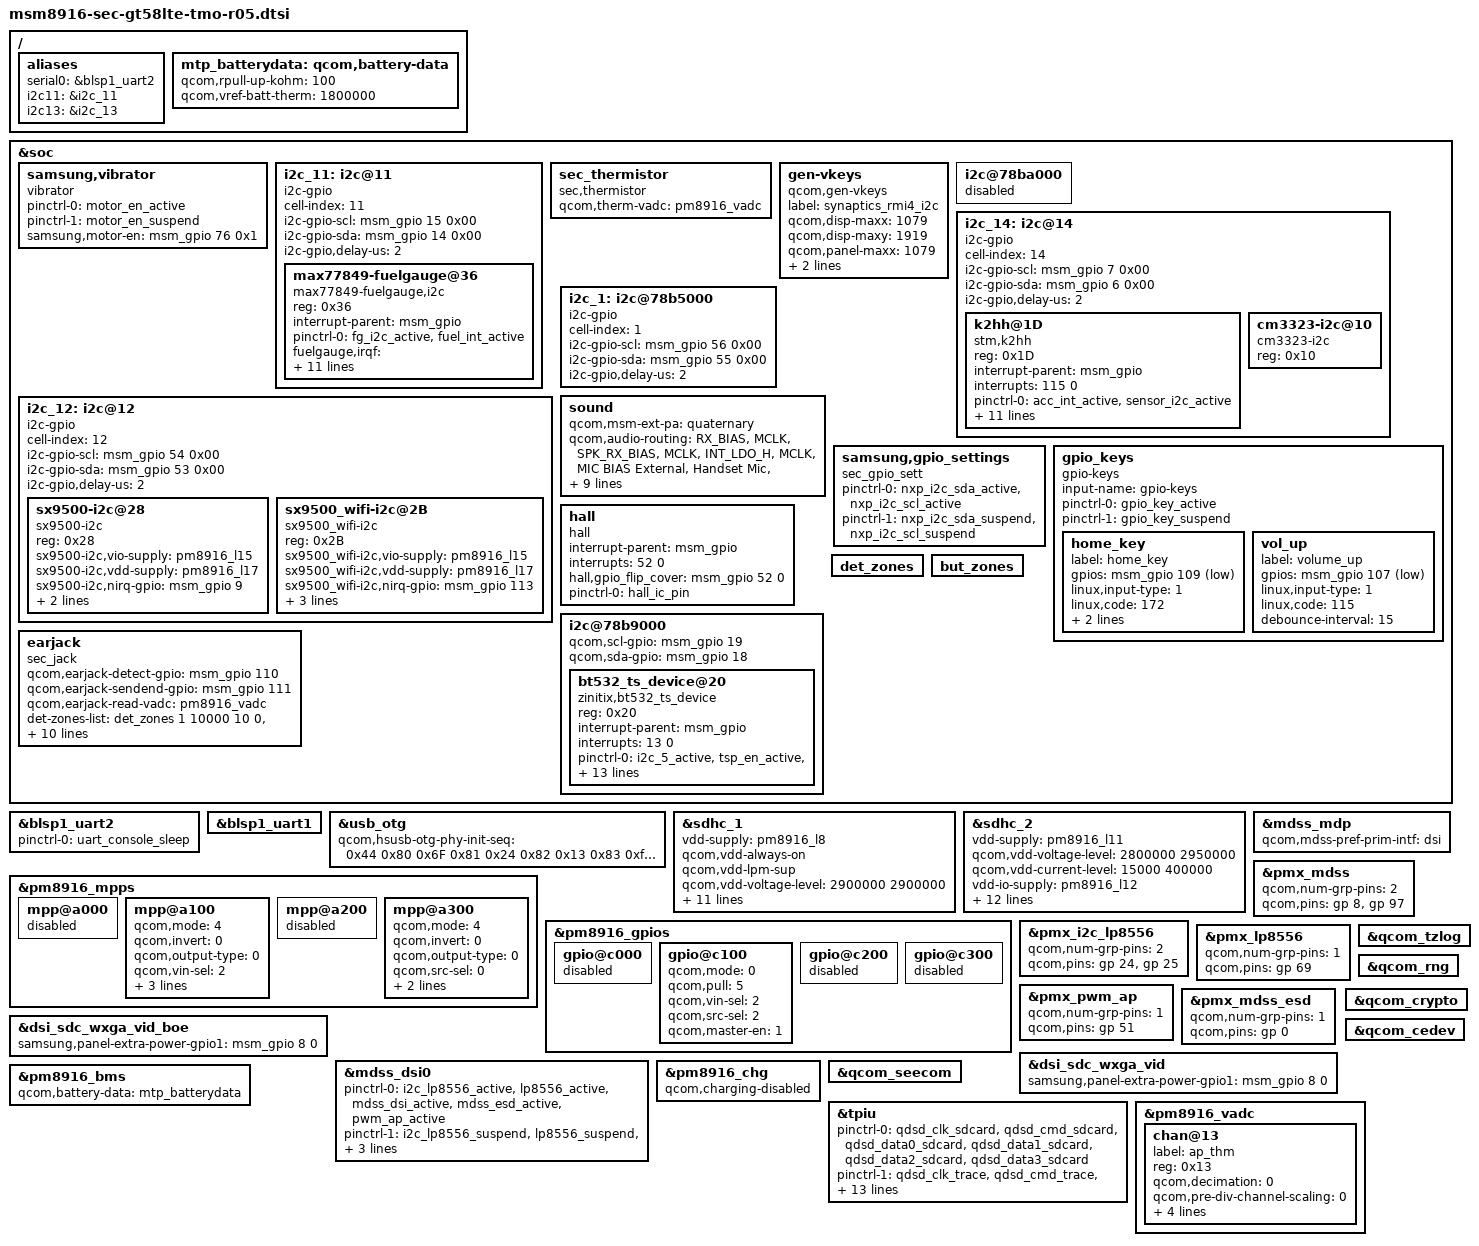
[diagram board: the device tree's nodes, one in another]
/* Copyright (c) 2014, The Linux Foundation. All rights reserved.
 *
 * This program is free software; you can redistribute it and/or modify
 * it under the terms of the GNU General Public License version 2 and
 * only version 2 as published by the Free Software Foundation.
 *
 * This program is distributed in the hope that it will be useful,
 * but WITHOUT ANY WARRANTY; without even the implied warranty of
 * MERCHANTABILITY or FITNESS FOR A PARTICULAR PURPOSE.  See the
 * GNU General Public License for more details.
 */

#include "msm8916.dtsi"
#include "msm8916-pinctrl-sec-gt58lte-tmo-r05.dtsi"
#include "msm8916-camera-sensor-gt58.dtsi"
#include "msm8916-sec-gt5note8lte-tmo-battery-r00.dtsi"
#include "msm8916-max77849-gt5note8-r01.dtsi"
#include "../../../../../../drivers/video/msm/mdss/samsung/S6D7AA0_LSL080AL03/dsi_panel_S6D7AA0_LSL080AL03_xga_video.dtsi"
#include "../../../../../../drivers/video/msm/mdss/samsung/S6D7AA0_LSL080AL03_BOE/dsi_panel_S6D7AA0_LSL080AL03_BOE_xga_video.dtsi"
/ {
	aliases {
		serial0 = &blsp1_uart2;
		i2c11 = &i2c_11;
		i2c13 = &i2c_13;
	};
};

&soc {
	samsung,vibrator {
	        pinctrl-names = "tlmm_motor_en_active","tlmm_motor_en_suspend";
	        pinctrl-0 = <&motor_en_active>;
	        pinctrl-1 = <&motor_en_suspend>;
	        compatible = "vibrator";
	        samsung,motor-en = <&msm_gpio 76 0x1>;
	        status = "ok";
	};

       i2c_11:i2c@11 {
		cell-index = <11>;
		compatible = "i2c-gpio";
		i2c-gpio-scl = <&msm_gpio 15 0x00>;
		i2c-gpio-sda = <&msm_gpio 14 0x00>;
		i2c-gpio,delay-us = <2>;
		#address-cells = <1>;
		#size-cells = <0>;

		max77849-fuelgauge@36{
			compatible = "max77849-fuelgauge,i2c";
			reg = <0x36>;
			interrupt-parent = <&msm_gpio>;
			pinctrl-names = "default";
			pinctrl-0 = <&fg_i2c_active &fuel_int_active>;
			fuelgauge,irqf = "IRQF_TRIGGER_FALLING + IRQF_ONESHOT + IRQF_NO_SUSPEND";
			fuelgauge,fuel_int = <&msm_gpio 121 0x1>;
			fuelgauge,capacity_max = <1000>;
			fuelgauge,capacity_max_margin = <50>;
			fuelgauge,capacity_min = <0>;
			fuelgauge,capacity_calculation_type = <0x1F>;
			fuelgauge,fuel_alert_soc = <1>;
			fuelgauge,using_temp_compensation;
			fuelgauge,low_temp_limit = <(-100)>;
			fuelgauge,low_temp_recovery = <(-80)>;
			fuelgauge,low_temp_valrt = <0xAA>;		/* VALRT is 3400V */
		};
	};

	sec_thermistor {
		compatible = "sec,thermistor";
		qcom,therm-vadc = <&pm8916_vadc>;
	};

	gen-vkeys {
		compatible = "qcom,gen-vkeys";
		label = "synaptics_rmi4_i2c";
		qcom,disp-maxx = <1079>;
		qcom,disp-maxy = <1919>;
		qcom,panel-maxx = <1079>;
		qcom,panel-maxy = <2084>;
		qcom,key-codes = <158 139 172 217>;
	};

	i2c@78ba000 { /* BLSP1 QUP6 */
		status = "disabled";
	};

       i2c_14:i2c@14 {
		cell-index = <14>;
		compatible = "i2c-gpio";
		i2c-gpio-scl = <&msm_gpio 7 0x00>;
		i2c-gpio-sda = <&msm_gpio 6 0x00>;
		i2c-gpio,delay-us = <2>;
		#address-cells = <1>;
		#size-cells = <0>;
		k2hh@1D {
			compatible = "stm,k2hh";
			reg = <0x1D>;
			interrupt-parent = <&msm_gpio>;
			interrupts = <115 0>;
			pinctrl-names = "default";
			pinctrl-0 = <&acc_int_active &sensor_i2c_active>;
			stm,irq_gpio = <&msm_gpio 115 0x00>;
			stm,vio-supply = <&pm8916_l5>;
			stm,vdd-supply = <&pm8916_l17>;
			stm,axis_map_x = <1>;
			stm,axis_map_y = <0>;
			stm,axis_map_z = <2>;
			stm,negate_x = <1>;
			stm,negate_y = <0>;
			stm,negate_z = <1>;
			stm,poll_interval = <100>;
			stm,min_interval = <2>;
		};
		cm3323-i2c@10 {
			compatible = "cm3323-i2c";
			reg = <0x10>;
		};
	};

	i2c_12:i2c@12 {
		cell-index = <12>;
		compatible = "i2c-gpio";
		i2c-gpio-scl = <&msm_gpio 54 0x00>;
		i2c-gpio-sda = <&msm_gpio 53 0x00>;
		i2c-gpio,delay-us = <2>;
		#address-cells = <1>;
		#size-cells = <0>;
		sx9500-i2c@28 {
			compatible = "sx9500-i2c";
			reg = <0x28>;
			sx9500-i2c,vio-supply = <&pm8916_l15>;
			sx9500-i2c,vdd-supply = <&pm8916_l17>;
			sx9500-i2c,nirq-gpio = <&msm_gpio 9 0x00>;
			sx9500-i2c,i2c-pull-up = <1>;
			pinctrl-names = "default";
			pinctrl-0 = <&grip_i2c_active &grip_int_active>;
		};
		sx9500_wifi-i2c@2B {
			compatible = "sx9500_wifi-i2c";
			reg = <0x2B>;
			sx9500_wifi-i2c,vio-supply = <&pm8916_l15>;
			sx9500_wifi-i2c,vdd-supply = <&pm8916_l17>;
			sx9500_wifi-i2c,nirq-gpio = <&msm_gpio 113 0x00>;
			sx9500_wifi-i2c,i2c-pull-up = <1>;
			pinctrl-names = "default";
			pinctrl-0 = <&grip_i2c_active &grip_wifi_int_active>;
		};
	};

	i2c_1: i2c@78b5000 {
		cell-index = <1>;
			compatible = "i2c-gpio";
			i2c-gpio-scl = <&msm_gpio 56 0x00>;
			i2c-gpio-sda = <&msm_gpio 55 0x00>;
			i2c-gpio,delay-us = <2>;
			#address-cells = <1>;
			#size-cells = <0>;
	};

	/* Over-riding model specific changes */
	sound {
		qcom,msm-ext-pa = "quaternary";
		qcom,audio-routing =
			"RX_BIAS", "MCLK",
			"SPK_RX_BIAS", "MCLK",
			"INT_LDO_H", "MCLK",
			"MIC BIAS External", "Handset Mic",
			"MIC BIAS External", "Secondary Mic",
			"AMIC1", "MIC BIAS External",
			"AMIC2", "Headset Mic",
			"AMIC3", "MIC BIAS External";
		pinctrl-names = "cdc_lines_act",
				"cdc_lines_sus",
				"cdc_lines_quat_ext_act",
				"cdc_lines_quat_ext_sus";
		pinctrl-0 = <&cdc_pdm_lines_act>;
		pinctrl-1 = <&cdc_pdm_lines_sus>;
		pinctrl-2 = <&cdc_pdm_lines_act &ext_cdc_tlmm_lines_act>;
		pinctrl-3 = <&cdc_pdm_lines_sus &ext_cdc_tlmm_lines_sus>;
	};

	samsung,gpio_settings{
		compatible = "sec_gpio_sett";
		pinctrl-names = "sec_gpio_active","sec_gpio_suspend";
		pinctrl-0 = <&nxp_i2c_sda_active &nxp_i2c_scl_active>;
		pinctrl-1 = <&nxp_i2c_sda_suspend &nxp_i2c_scl_suspend>;
	};
};

&blsp1_uart2 {
	status = "ok";
	pinctrl-names = "default";
	pinctrl-0 = <&uart_console_sleep>;
};

&soc {
	gpio_keys {
		compatible = "gpio-keys";
		input-name = "gpio-keys";
		pinctrl-names = "tlmm_gpio_key_active","tlmm_gpio_key_suspend";
		pinctrl-0 = <&gpio_key_active>;
		pinctrl-1 = <&gpio_key_suspend>;

		home_key {
			label = "home_key";
			gpios = <&msm_gpio 109 0x1>;
			linux,input-type = <1>;
			linux,code = <172>;
			gpio-key,wakeup;
			debounce-interval = <15>;
		};

		vol_up {
			label = "volume_up";
			gpios = <&msm_gpio 107 0x1>;
			linux,input-type = <1>;
			linux,code = <115>;
			debounce-interval = <15>;
		};
	};
	hall {
		status = "okay";
		compatible = "hall";
		interrupt-parent = <&msm_gpio>;
		interrupts = <52 0>;
		hall,gpio_flip_cover = <&msm_gpio 52 0>;
		pinctrl-names = "pmx_hall_ic_pin";
		pinctrl-0 = <&hall_ic_pin>;
	};

/*	i2c_10:i2c@10 {
		cell-index = <10>;
		compatible = "i2c-gpio";
		i2c-gpio-scl = <&msm_gpio 17  0x00>;
		i2c-gpio-sda = <&msm_gpio 16 0x00>;
		i2c-gpio,delay-us = <1>;
		#address-cells = <1>;
		#size-cells = <0>;

		tc360@20 {
			compatible = "coreriver,coreriver-tkey";
			reg = <0x20>;
			interrupt-parent = <&msm_gpio>;
			interrupts = <98 0>;
			pinctrl-names = "tkey_gpio_active","tkey_gpio_suspend";
			pinctrl-0 = <&tkey_i2c_active>;
			pinctrl-1 = <&tkey_i2c_active>;

			//coreriver,vcc_en_ldo_name = "max77826_ldo15";
			coreriver,vcc_en-gpio = <&msm_gpio 97 0x00>;
			//coreriver,vdd_led_ldo_name = "max77826_ldo12";
			coreriver,scl-gpio = <&msm_gpio 17 0x00>;
			coreriver,sda-gpio = <&msm_gpio 16 0x00>;
			coreriver,irq-gpio = <&msm_gpio  98 0x00>;
			coreriver,tkey-keycodes = <254 158>;
			coreriver,i2c-pull-up = <1>;
			coreriver,gpio_seperated = <1>;
			//coreriver,firm-up;

		};
	};*/

        i2c@78b9000 { /* BLSP1 QUP5 */
		qcom,scl-gpio = <&msm_gpio 19 0>;
		qcom,sda-gpio = <&msm_gpio 18 0>;
                status = "okay";
                bt532_ts_device@20 {
                        compatible = "zinitix,bt532_ts_device";
                        reg = <0x20>;
                        interrupt-parent = <&msm_gpio>;
                        interrupts = <13 0>;
                        pinctrl-names = "tsp_en_gpio_active", "tsp_en_gpio_suspend";
                        pinctrl-0 = <&i2c_5_active &tsp_en_active &tsp_id_active &int_active>;
                        pinctrl-1 = <&i2c_5_sleep &tsp_en_suspend &tsp_id_suspend>;
                        vddo-supply = <&pm8916_l6>;
                        zinitix,vdd_en-gpio = <&msm_gpio 73 0x00>;
                        zinitix,irq-gpio = <&msm_gpio 13 0x00>;
                        zinitix,vendor1 = <&msm_gpio 114 0x00>;
                        zinitix,x_resolution = <768>;
                        zinitix,y_resolution = <1024>;
                        zinitix,page_size = <128>;
                        zinitix,orientation = <0>;
                        zinitix,tsp_vdd_supply_type = <0>;
                        zinitix,pname = "GT5NOTE8";

                };
	};

	sec_thermistor {
		compatible = "sec,thermistor";
		qcom,therm-vadc = <&pm8916_vadc>;
	};

	det_zones: det_zones {
		#list-det-cells = <4>;
	};

	but_zones: but_zones {
		#list-but-cells = <3>;
	};

	earjack {
		compatible = "sec_jack";
		qcom,earjack-detect-gpio = <&msm_gpio 110 0x0>;
		qcom,earjack-sendend-gpio = <&msm_gpio 111 0x0>;
		qcom,earjack-read-vadc = <&pm8916_vadc>;

		det-zones-list = <&det_zones 1 10000 10 0>,
				 <&det_zones 970 10000 10 0>,
				 <&det_zones 1900 10000 10 1>,
				 <&det_zones 2800 10000 10 1>;
		but-zones-list = <&but_zones 0 1 303>,
				 <&but_zones 3 304 350>,
				 <&but_zones 1 351 469>,
				 <&but_zones 2 470 750>;
		btn-adc-read-count = <8>;
		mpp-channel-scaling = <2 1 1>;
		pinctrl-names = "earjack_gpio_active","earjack_gpio_suspend";
		pinctrl-0 = <&earjack_det_act &earjack_switch_act>;
		pinctrl-1 = <&earjack_det_sus &earjack_switch_sus>;
	};
};

&blsp1_uart1 {
	status = "ok";
};

&usb_otg {
	qcom,hsusb-otg-phy-init-seq =
					<0x44 0x80 0x6F 0x81 0x24 0x82 0x13 0x83 0xffffffff>;
};

&sdhc_1 {
	vdd-supply = <&pm8916_l8>;
	qcom,vdd-always-on;
	qcom,vdd-lpm-sup;
	qcom,vdd-voltage-level = <2900000 2900000>;
	qcom,vdd-current-level = <200 400000>;

	vdd-io-supply = <&pm8916_l5>;
	qcom,vdd-io-always-on;
	qcom,vdd-io-lpm-sup;
	qcom,vdd-io-voltage-level = <1800000 1800000>;
	qcom,vdd-io-current-level = <200 60000>;

	pinctrl-names = "active", "sleep";
	pinctrl-0 = <&sdc1_clk_on &sdc1_cmd_on &sdc1_data_on>;
	pinctrl-1 = <&sdc1_clk_off &sdc1_cmd_off &sdc1_data_off>;

	qcom,nonremovable;

	status = "ok";
};

&sdhc_2 {
	vdd-supply = <&pm8916_l11>;
	qcom,vdd-voltage-level = <2800000 2950000>;
	qcom,vdd-current-level = <15000 400000>;

	vdd-io-supply = <&pm8916_l12>;
	qcom,vdd-io-voltage-level = <1800000 2950000>;
	qcom,vdd-io-current-level = <200 50000>;

	pinctrl-names = "active", "sleep";
	pinctrl-0 = <&sdc2_clk_on &sdc2_cmd_on &sdc2_data_on &sdc2_cd_on>;
	pinctrl-1 = <&sdc2_clk_off &sdc2_cmd_off &sdc2_data_off &sdc2_cd_off>;

	#address-cells = <0>;
	interrupt-parent = <&sdhc_2>;
	interrupts = <0 1 2>;
	#interrupt-cells = <1>;
	interrupt-map-mask = <0xffffffff>;
	interrupt-map = <0 &intc 0 125 0
			1 &intc 0 221 0
			2 &msm_gpio 38 0>;
	interrupt-names = "hc_irq", "pwr_irq", "status_irq";
	cd-gpios = <&msm_gpio 38 0x1>;

	status = "ok";
};

&pm8916_mpps {
	mpp@a000 { /* MPP 1 */
		/* VDD_PX */
		status = "disabled";
	};

	mpp@a100 { /* MPP 2 */
		status = "ok";
		qcom,mode = <4>; // AIN input
		qcom,invert = <0>; //No Invert
		qcom,output-type = <0>; //CMOS
		qcom,vin-sel = <2>; //PM8971_S3 1.8v
		qcom,src-sel = <0>; //MPP Constant
		qcom,ain-route = <1>; // QPNP_PIN_AIN_AMUX_CH6 = 1 for MPP2
		qcom,master-en = <1>; // Function constant
	};

	mpp@a200 { /* MPP 3 */
		/* VREF DAC */
		status = "disabled";
	};

	mpp@a300 { /* MPP 4 */
		status = "ok";
		qcom,mode = <4>;		/* AIN Input */
		qcom,invert = <0>;		/* Disable invert */
		qcom,output-type = <0>;		/* CMOS */
		qcom,src-sel = <0>;		/* /MPP Constant */
		qcom,ain-route = <3>;		/* QPNP_PIN_AIN_AMUX_CH8 = 3 for MPP4 */
		qcom,master-en = <1>;		/* Enable MPP */
	};
};

&pm8916_gpios {
	gpio@c000 { /* GPIO 1 */
		/* Battery UICC Alarm */
		status = "disabled";
	};

	gpio@c100 { /* GPIO 2 */
		/* NFC_CLK_REQ */
		qcom,mode = <0>; /* QPNP_PIN_MODE_DIG_IN */
		qcom,pull = <5>; /* QPNP_PIN_PULL_NO */
		qcom,vin-sel = <2>; /* QPNP_PIN_VIN2 */
		qcom,src-sel = <2>; /* QPNP_PIN_SEL_FUNC_1 */
		qcom,master-en = <1>;
	};

	gpio@c200 { /* GPIO 3 */
		/* External regulator control for WTR */
		status = "disabled";
	};

	gpio@c300 { /* GPIO 4 */
		/* External regulator control for APC */
		status = "disabled";
	};
};

&mdss_mdp {
	qcom,mdss-pref-prim-intf = "dsi";
};

&pmx_mdss {
	qcom,num-grp-pins = <2>;
	qcom,pins = <&gp 8>, <&gp 97>;
};

&pmx_i2c_lp8556 {
	qcom,num-grp-pins = <2>;
	qcom,pins = <&gp 24>, <&gp 25>;
};

&pmx_lp8556 {
	qcom,num-grp-pins = <1>;
	qcom,pins = <&gp 69>;
};

&pmx_pwm_ap {
	qcom,num-grp-pins = <1>;
	qcom,pins = <&gp 51>;
};

&pmx_mdss_esd {
	qcom,num-grp-pins = <1>;
	qcom,pins = <&gp 0>;
};

&dsi_sdc_wxga_vid_boe{
    samsung,panel-extra-power-gpio1 = <&msm_gpio 8 0>;
};

&dsi_sdc_wxga_vid{
	samsung,panel-extra-power-gpio1 = <&msm_gpio 8 0>;
};

&mdss_dsi0 {
	pinctrl-names = "mdss_default", "mdss_sleep";
	pinctrl-0 = <&i2c_lp8556_active &lp8556_active &mdss_dsi_active &mdss_esd_active &pwm_ap_active>;
	pinctrl-1 = <&i2c_lp8556_suspend &lp8556_suspend &mdss_dsi_suspend &mdss_esd_suspend &pwm_ap_suspend>;
	qcom,platform-reset-gpio = <&msm_gpio 97 0>;
};

&pm8916_chg {
	status = "ok";
	qcom,charging-disabled;
};

/ {
	mtp_batterydata: qcom,battery-data {
		qcom,rpull-up-kohm = <100>;
		qcom,vref-batt-therm = <1800000>;

		#include "batterydata-palladium.dtsi"
	};
};

&pm8916_bms {
	status = "ok";
	qcom,battery-data = <&mtp_batterydata>;
};
/*
&spmi_bus {
	qcom,pm8916@0 {
		qcom,leds@a100 {
			status = "okay";
			qcom,led_mpp_2 {
				label = "mpp";
				linux,name = "button-backlight";
				linux,default-trigger = "none";
				qcom,default-state = "off";
				qcom,max-current = <40>;
				qcom,current-setting = <5>;
				qcom,id = <6>;
				qcom,mode = "manual";
				qcom,source-sel = <1>;
				qcom,mode-ctrl = <0x60>;
			};
		};
	};
};
*/
&qcom_tzlog {
	status = "okay";
};

&qcom_rng {
	status = "okay";
};

&qcom_crypto {
	status = "okay";
};

&qcom_cedev {
	status = "okay";
};

&qcom_seecom {
	status = "okay";
};

/* CoreSight */
&tpiu {
      pinctrl-names = "sdcard", "trace", "swduart",
		      "swdtrc", "jtag", "spmi";
       /* NIDnT */
      pinctrl-0 = <&qdsd_clk_sdcard &qdsd_cmd_sdcard
                  &qdsd_data0_sdcard &qdsd_data1_sdcard
                  &qdsd_data2_sdcard &qdsd_data3_sdcard>;
      pinctrl-1 = <&qdsd_clk_trace &qdsd_cmd_trace
                  &qdsd_data0_trace &qdsd_data1_trace
                  &qdsd_data2_trace &qdsd_data3_trace>;
      pinctrl-2 = <&qdsd_cmd_swduart &qdsd_data0_swduart
                  &qdsd_data1_swduart &qdsd_data2_swduart
                  &qdsd_data3_swduart>;
      pinctrl-3 = <&qdsd_clk_swdtrc &qdsd_cmd_swdtrc
                  &qdsd_data0_swdtrc &qdsd_data1_swdtrc
                  &qdsd_data2_swdtrc &qdsd_data3_swdtrc>;
      pinctrl-4 = <&qdsd_cmd_jtag &qdsd_data0_jtag
                  &qdsd_data1_jtag &qdsd_data2_jtag
                  &qdsd_data3_jtag>;
      pinctrl-5 = <&qdsd_clk_spmi &qdsd_cmd_spmi
                  &qdsd_data0_spmi &qdsd_data3_spmi>;
};

&pm8916_vadc {
	chan@13 {
		label = "ap_thm";
		reg = <0x13>;	/* channel 19 for MPP4 , 1:1scale */
		qcom,decimation = <0>;
		qcom,pre-div-channel-scaling = <0>;	/* 1:1scale */
		qcom,calibration-type = "ratiometric";
		qcom,scale-function = <1>;
		qcom,hw-settle-time = <2>;
		qcom,fast-avg-setup = <0>;
	};
};
